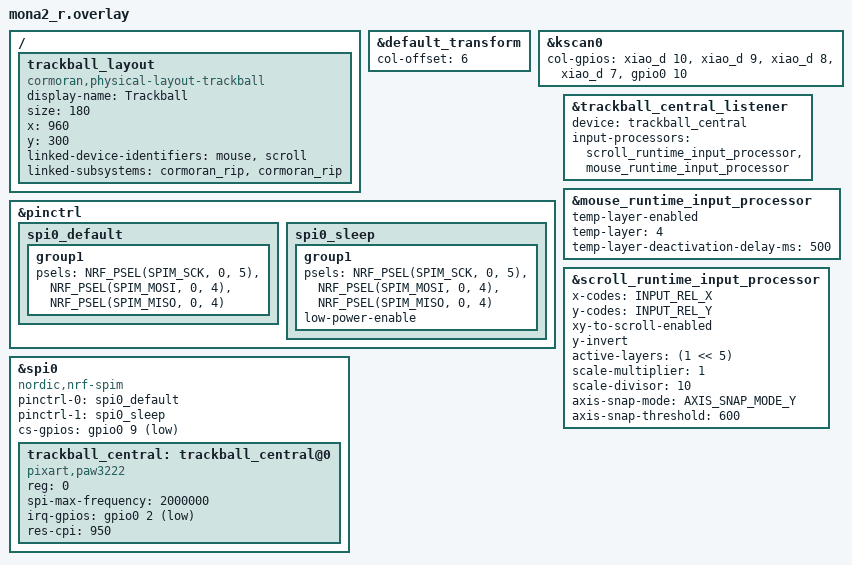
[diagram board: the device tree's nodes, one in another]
#include "mona2.dtsi"
#include <input/processors.dtsi>
#include <input/processors/runtime-input-processor.dtsi>
#include <dt-bindings/zmk/runtime_input_processor.h>
#include <zephyr/dt-bindings/input/input-event-codes.h>

&default_transform {
    col-offset = <6>;
};

&kscan0 {
        col-gpios
            = <&xiao_d 10 GPIO_ACTIVE_HIGH>
            , <&xiao_d 9 GPIO_ACTIVE_HIGH> 
            , <&xiao_d 8 GPIO_ACTIVE_HIGH> 
            , <&xiao_d 7 GPIO_ACTIVE_HIGH> 
            , <&gpio0 10 GPIO_ACTIVE_HIGH>
            ;
};


&pinctrl {
    spi0_default: spi0_default {    //通常時(SPI通信中)のピン構成
        group1 {
            psels = <NRF_PSEL(SPIM_SCK, 0, 5)>, //P0.05を指定(SCLK)
                <NRF_PSEL(SPIM_MOSI, 0, 4)>,    //P0.04を指定(SDIOだからMOSI,MISO両方の役割を担う)
                <NRF_PSEL(SPIM_MISO, 0, 4)>;
        };
    };

    spi0_sleep: spi0_sleep {    //スリープ時のピン構成(省電力)
        group1 {
            psels = <NRF_PSEL(SPIM_SCK, 0, 5)>,
                <NRF_PSEL(SPIM_MOSI, 0, 4)>,
                <NRF_PSEL(SPIM_MISO, 0, 4)>;
            low-power-enable;
        };
    };
};


&spi0 {
    status = "okay";
    compatible = "nordic,nrf-spim"; //マイコンがnRFシリーズ
    pinctrl-0 = <&spi0_default>;
    pinctrl-1 = <&spi0_sleep>;
    pinctrl-names = "default", "sleep";
    cs-gpios = <&gpio0 9 GPIO_ACTIVE_LOW>;  //P0.09を指定(CS)

    trackball_central: trackball_central@0 {
        status = "okay";
        compatible = "pixart,paw3222";  //トラボセンサ用のドライバとバインド
        reg = <0>;
        spi-max-frequency = <2000000>;
        irq-gpios = <&gpio0 2 (GPIO_ACTIVE_LOW | GPIO_PULL_UP)>; //P0.02を指定(MOTION)
        res-cpi = <950>;
    };
};


// Overrides for the input listener node
//
// 旧構成（gohanda11 threshold-temp-layer + 標準 input processor + kot149 scroll-snap）と
// 同じ向き・量になるよう、DYA Studio から変更できる runtime input processor に置き換えた。
//   ドライバ出力 = そのまま（PAW3222 は反転なし。dtsi の Y 反転は overlay で上書きされ、もともと効いていない）
//   マウス      = そのまま、動かすと MOUSE レイヤー(4)へ自動切り替え、500ms で解除
//                 ※ 旧構成の「100 カウント動いてから」のしきい値は無くなった
//                   （gohanda11 版が ZMK main でビルドできないため。runtime processor には移動量しきい値が無い）
//   スクロール  = SCROLL レイヤー(5)のときだけ。X→横 / Y→縦、縦は反転、1/10 倍、縦方向にスナップ
// scroll を先に置くことで、SCROLL レイヤー中は mouse 側（オートマウス）を通らない。
&trackball_central_listener {
    status = "okay";
    device = <&trackball_central>;
    input-processors = <&scroll_runtime_input_processor &mouse_runtime_input_processor>;
};

&mouse_runtime_input_processor {
    temp-layer-enabled;
    temp-layer = <4>;                           // 4 = MOUSE（オートマウスレイヤー）
    temp-layer-deactivation-delay-ms = <500>;   // 旧 zip_threshold_temp_layer 4 500 と同じ
};

&scroll_runtime_input_processor {
    x-codes = <INPUT_REL_X>;
    y-codes = <INPUT_REL_Y>;
    xy-to-scroll-enabled;
    y-invert;                                   // 旧 zip_scroll_transform INPUT_TRANSFORM_Y_INVERT
    active-layers = <(1 << 5)>;                 // 5 = SCROLL
    scale-multiplier = <1>;
    scale-divisor = <10>;                       // 旧 zip_scroll_scaler 1 10
    axis-snap-mode = <AXIS_SNAP_MODE_Y>;        // 縦優先（旧 zip_scroll_snap の代わり）
    axis-snap-threshold = <600>;
};

/ {
    // DYA Studio のキーマップ表示にトラックボールを描く（表示専用）
    trackball_layout: trackball_layout {
        compatible = "cormoran,physical-layout-trackball";
        display-name = "Trackball";
        size = <180>;
        x = <960>;
        y = <300>;
        linked-device-identifiers = "mouse", "scroll";
        linked-subsystems = "cormoran_rip", "cormoran_rip";
    };
};
